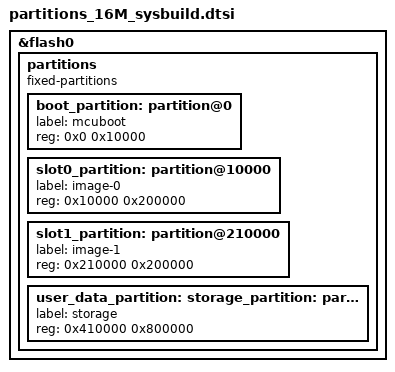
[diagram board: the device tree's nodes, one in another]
/*
 * Copyright (c) 2025 Beechwoods Software, Inc.
 *
 * SPDX-License-Identifier: Apache-2.0
 */

&flash0 {
	status = "okay";

	partitions {
		compatible = "fixed-partitions";
		#address-cells = <0x1>;
		#size-cells = <0x1>;

		boot_partition: partition@0 {
			label = "mcuboot";
			reg = <0x0 0x10000>;
		};

		slot0_partition: partition@10000 {
			label = "image-0";
			reg = <0x10000 0x200000>;
		};

		slot1_partition: partition@210000 {
			label = "image-1";
			reg = <0x210000 0x200000>;
		};

		user_data_partition: storage_partition: partition@410000 {
			label = "storage";
			reg = <0x410000 0x800000>;
		};
	};
};
